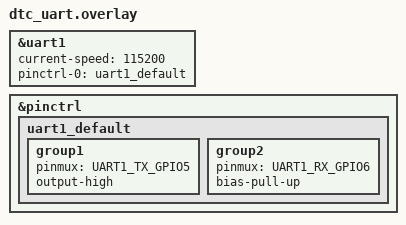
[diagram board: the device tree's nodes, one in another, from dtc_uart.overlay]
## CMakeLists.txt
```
# SPDX-License-Identifier: Apache-2.0

cmake_minimum_required(VERSION 3.20.0)
set(CONF_FILE prj.conf)
set(DTC_OVERLAY_FILE dtc_uart.overlay)

find_package(Zephyr REQUIRED HINTS $ENV{ZEPHYR_BASE})

FILE(GLOB app_sources src/*.c)
target_sources(app PRIVATE ${app_sources}
                            ./src/motordriver.c
                            ./src/rovermotor.c
                            ./src/roveruart.c
                            )
                            

project(Prac2)
```

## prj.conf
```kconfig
CONFIG_LOG=y

CONFIG_CBPRINTF_FP_SUPPORT=y

CONFIG_SHELL=y
CONFIG_SHELL_BACKENDS=y
CONFIG_SHELL_BACKEND_SERIAL=y


CONFIG_MAIN_STACK_SIZE=4096
CONFIG_I2C=y
CONFIG_SERIAL=y
CONFIG_UART_INTERRUPT_DRIVEN=y
CONFIG_UART_CONSOLE=y
```

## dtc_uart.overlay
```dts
&uart1 {
	status = "okay";
	current-speed = <115200>;
	pinctrl-0 = <&uart1_default>;
	pinctrl-names = "default";
};

&pinctrl {

	uart1_default: uart1_default {
		group1 {
			pinmux = <UART1_TX_GPIO5>;
			output-high;
		};
		group2 {
			pinmux = <UART1_RX_GPIO6>;
			bias-pull-up;
		};
	};
};
```

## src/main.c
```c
#include <stdlib.h>

#include <zephyr/kernel.h>
#include <zephyr/logging/log.h>
#include <zephyr/device.h>
#include <zephyr/shell/shell.h>
#include <zephyr/drivers/i2c.h>
#include <zephyr/drivers/uart.h>
#include "rovermotor.h"
#include "roveruart.h"
#define LOG_LEVEL 4
LOG_MODULE_REGISTER(main);

//  Global to pass to shell commands. 
struct rovermotor_info motor_control_handle; 
struct roveruart_info uart_control_handle; 
const struct device* i2c_dev = DEVICE_DT_GET(DT_NODELABEL(i2c0));
const struct device* uart_dev = DEVICE_DT_GET(DT_NODELABEL(uart1));

static int rover_cmd_cb(const struct shell* shell, size_t argc, char** argv) 
{
	int8_t vel = atoi(argv[1]); 
	int angle_percent = atoi(argv[2]); 
	float angle = ((float) (angle_percent)) / 100; 
	LOG_INF("Commanding speed: %hhi, angle: %f", vel, angle);
	rovermotor_send_instruction(&motor_control_handle, angle, vel);
	return 0;
}

static int reset_angle_cmd_cb(const struct shell* shell, size_t argc, char** argv) 
{
	roveruart_reset_angle(&uart_control_handle);
	LOG_INF("Resetting angle");
	return 0;
}
void main(void) 
{

	rovermotor_init(0x5D, 0xAB, i2c_dev, &motor_control_handle); 
	roveruart_init(uart_dev, &uart_control_handle); 
	LOG_INF("Initialized motor handler");

	SHELL_CMD_ARG_REGISTER(
        rover,
        NULL,
        "rover [speed] [angle]: set speed and angle \n"
		"speed from -127 to 127, angle from -100 to 100 (int)",
        rover_cmd_cb,
        3,
        0
    );
	SHELL_CMD_ARG_REGISTER(
        reset_angle,
        NULL,
        "Reset angle refernce\n",
		reset_angle_cmd_cb,
        0,
        0
    );
	rover_position_info_t position; 
	while (1)
	{
		// Do nothing - shell command handles it all. 
		k_sleep(K_MSEC(1000));
		int res = roveruart_get_new_position(&uart_control_handle, &position);
		if (res) {
			//LOG_INF("No new messages");
		} else {
			LOG_INF("Got position: (%hhu, %hhu)", position.x, position.y); 
		}
	}
	
	
}
```

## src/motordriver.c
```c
#include "motordriver.h"
LOG_MODULE_REGISTER(motordriver);

/**
 * initializes an instance of a driver for the Sparkfun Qwiic Motor Driver /
 * Sparkfun SCMD motor driver, on given uart device, with given device address
 */
void motordriver_init(const struct device* dev, uint8_t device_addr) 
{

    if (!device_is_ready(dev)) {
		LOG_ERR("I2C: Device is not ready.\n");
		return;
	}
    // dummy read - check the device we expect is on this bus. 
    uint8_t res;
    int status = i2c_reg_read_byte(dev, device_addr, SCMD_ID, &res);
    int num_tries = 0; 
    while (res != ID_WORD) 
    {
        LOG_INF("Couldn't get valid ID yet ... ");

        k_sleep(K_MSEC(100));
        status = i2c_reg_read_byte(dev, device_addr, SCMD_ID, &res);
        if (num_tries++ > CONN_MAX_NUM_TRIES) {
            LOG_ERR("Couldn't find driver with addr %x", device_addr);
            return; 
        };

    }
    if (status) {
        LOG_ERR("Dummy read failed");
    } else {
        LOG_INF("Found motor driver with id %x", res);
    }
    i2c_reg_write_byte(dev, device_addr, SCMD_DRIVER_ENABLE, 0x01);

    i2c_reg_read_byte(dev, device_addr, SCMD_DRIVER_ENABLE, &res);
    i2c_reg_write_byte(dev, device_addr, SCMD_BRIDGE, 0x01);
}

int motordriver_send_pwm(const struct device* dev, uint8_t device_addr, uint8_t val)
{
    int res = i2c_reg_write_byte(dev, device_addr, SCMD_MA_DRIVE, val);
    if (res) {
        return res;
    }
    res = i2c_reg_write_byte(dev, device_addr, SCMD_MB_DRIVE, val);
    return res;
    
}
```

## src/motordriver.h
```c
#ifndef _MOTOR_DRIVER_H_
#define _MOTOR_DRIVER_H_
#include <zephyr/logging/log.h>
#include <zephyr/device.h>
#include <zephyr/drivers/i2c.h>


//defaults ( Set config in PSoC, use for reference in Arduino )   
#define ID_WORD                    0xA9  //Device ID to be programmed into memory for reads
#define START_SLAVE_ADDR           0x50  //Start address of slaves
#define MAX_SLAVE_ADDR             0x5F  //Max address of slaves
#define MASTER_LOCK_KEY            0x9B
#define USER_LOCK_KEY              0x5C
#define FIRMWARE_VERSION           0x07
#define POLL_ADDRESS               0x4A  //Address of an unasigned, ready slave
#define MAX_POLL_LIMIT             0xC8  //200

//SCMD_STATUS_1 bits
#define SCMD_ENUMERATION_BIT       0x01
#define SCMD_BUSY_BIT              0x02
#define SCMD_REM_READ_BIT          0x04
#define SCMD_REM_WRITE_BIT         0x08
#define SCMD_HW_EN_BIT             0x10
 
//SCMD_CONTROL_1 bits
#define SCMD_FULL_RESET_BIT        0x01
#define SCMD_RE_ENUMERATE_BIT      0x02
    
//SCMD_FSAFE_CTRL bits and masks
#define SCMD_FSAFE_DRIVE_KILL      0x01
#define SCMD_FSAFE_RESTART_MASK    0x06
	#define SCMD_FSAFE_REBOOT          0x02
	#define SCMD_FSAFE_RE_ENUM         0x04
#define SCMD_FSAFE_CYCLE_USER      0x08
#define SCMD_FSAFE_CYCLE_EXP       0x10

//SCMD_MST_E_IN_FN bits and masks
#define SCMD_M_IN_RESTART_MASK    0x03
	#define SCMD_M_IN_REBOOT          0x01
	#define SCMD_M_IN_RE_ENUM         0x02
#define SCMD_M_IN_CYCLE_USER      0x04
#define SCMD_M_IN_CYCLE_EXP       0x08

//Address map
#define SCMD_FID                   0x00
#define SCMD_ID                    0x01
#define SCMD_SLAVE_ADDR            0x02
#define SCMD_CONFIG_BITS           0x03
#define SCMD_U_I2C_RD_ERR          0x04
#define SCMD_U_I2C_WR_ERR          0x05
#define SCMD_U_BUF_DUMPED          0x06
#define SCMD_E_I2C_RD_ERR          0x07
#define SCMD_E_I2C_WR_ERR          0x08
#define SCMD_LOOP_TIME	           0x09
#define SCMD_SLV_POLL_CNT          0x0A
#define SCMD_SLV_TOP_ADDR          0x0B
#define SCMD_MST_E_ERR             0x0C
#define SCMD_MST_E_STATUS          0x0D
#define SCMD_FSAFE_FAULTS          0x0E
#define SCMD_REG_OOR_CNT           0x0F
#define SCMD_REG_RO_WRITE_CNT      0x10
#define SCMD_GEN_TEST_WORD         0x11
#define SCMD_MOTOR_A_INVERT        0x12
#define SCMD_MOTOR_B_INVERT        0x13
#define SCMD_BRIDGE                0x14
#define SCMD_LOCAL_MASTER_LOCK     0x15
#define SCMD_LOCAL_USER_LOCK       0x16
#define SCMD_MST_E_IN_FN           0x17
#define SCMD_U_PORT_CLKDIV_U       0x18
#define SCMD_U_PORT_CLKDIV_L       0x19
#define SCMD_U_PORT_CLKDIV_CTRL    0x1A
#define SCMD_E_PORT_CLKDIV_U       0x1B
#define SCMD_E_PORT_CLKDIV_L       0x1C
#define SCMD_E_PORT_CLKDIV_CTRL    0x1D
#define SCMD_U_BUS_UART_BAUD       0x1E
#define SCMD_FSAFE_CTRL            0x1F
#define SCMD_MA_DRIVE              0x20
#define SCMD_MB_DRIVE              0x21
#define SCMD_S1A_DRIVE             0x22
#define SCMD_S1B_DRIVE             0x23
#define SCMD_S2A_DRIVE             0x24
#define SCMD_S2B_DRIVE             0x25
#define SCMD_S3A_DRIVE             0x26
#define SCMD_S3B_DRIVE             0x27
#define SCMD_S4A_DRIVE             0x28
#define SCMD_S4B_DRIVE             0x29
#define SCMD_S5A_DRIVE             0x2A
#define SCMD_S5B_DRIVE             0x2B
#define SCMD_S6A_DRIVE             0x2C
#define SCMD_S6B_DRIVE             0x2D
#define SCMD_S7A_DRIVE             0x2E
#define SCMD_S7B_DRIVE             0x2F
#define SCMD_S8A_DRIVE             0x30
#define SCMD_S8B_DRIVE             0x31
#define SCMD_S9A_DRIVE             0x32
#define SCMD_S9B_DRIVE             0x33
#define SCMD_S10A_DRIVE            0x34
#define SCMD_S10B_DRIVE            0x35
#define SCMD_S11A_DRIVE            0x36
#define SCMD_S11B_DRIVE            0x37
#define SCMD_S12A_DRIVE            0x38
#define SCMD_S12B_DRIVE            0x39
#define SCMD_S13A_DRIVE            0x3A
#define SCMD_S13B_DRIVE            0x3B
#define SCMD_S14A_DRIVE            0x3C
#define SCMD_S14B_DRIVE            0x3D
#define SCMD_S15A_DRIVE            0x3E
#define SCMD_S15B_DRIVE            0x3F
#define SCMD_S16A_DRIVE            0x40
#define SCMD_S16B_DRIVE            0x41

#define SCMD_INV_2_9               0x50
#define SCMD_INV_10_17             0x51
#define SCMD_INV_18_25             0x52
#define SCMD_INV_26_33             0x53
#define SCMD_BRIDGE_SLV_L          0x54
#define SCMD_BRIDGE_SLV_H          0x55

//#define SCMD_PAGE_SELECT           0x6F
#define SCMD_DRIVER_ENABLE         0x70
#define SCMD_UPDATE_RATE           0x71
#define SCMD_FORCE_UPDATE          0x72
#define SCMD_E_BUS_SPEED           0x73
#define SCMD_MASTER_LOCK           0x74
#define SCMD_USER_LOCK             0x75
#define SCMD_FSAFE_TIME            0x76
#define SCMD_STATUS_1              0x77
#define SCMD_CONTROL_1             0x78

#define SCMD_REM_ADDR              0x79
#define SCMD_REM_OFFSET            0x7A
#define SCMD_REM_DATA_WR           0x7B
#define SCMD_REM_DATA_RD           0x7C
#define SCMD_REM_WRITE             0x7D
#define SCMD_REM_READ              0x7E

extern void motordriver_init(const struct device* dev, uint8_t device_addr);

extern int motordriver_send_pwm(const struct device* dev, uint8_t device_addr, uint8_t val); 



#endif 
```

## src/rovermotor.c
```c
#include "rovermotor.h"
LOG_MODULE_REGISTER(rovermotor);

K_THREAD_STACK_DEFINE(rovermotor_handler_stack, ROVERMOTOR_STACK_SIZE);

/**
 * Initializes parameters stored in rovermotor handle motor_info. 
 * Creates handler thread and returns its thread ID. 
 * @param left_addr 7-bit i2c address of left-side motor controller
 * @param right_addr 7 bit i2c address of right side motor controller
 * @param dev zephyr i2c device that each motor driver is run on. 
 * @param motor_info uninitialized struct (it is initialized in this function). 
 */
k_tid_t rovermotor_init(
            uint8_t left_addr, 
            uint8_t right_addr, 
            const struct device* dev, 
            struct rovermotor_info* motor_info
            ) 
{
    motor_info->left_addr = left_addr;
    motor_info->right_addr = right_addr;
    motor_info->dev = dev; 
    
    k_msgq_init(
        &(motor_info->handler_queue), 
        motor_info->cmd_msg_buf, 
        sizeof(struct rover_queue_msg), 
        16
        );

    // Create thread and pass in handler struct to avoid global. 
    LOG_INF("Creating thread to handle rover motor control");
    return k_thread_create(&(motor_info->motor_thread_data), rovermotor_handler_stack,
		K_THREAD_STACK_SIZEOF(rovermotor_handler_stack),
		rovermotor_handler,
		(void*) (motor_info), NULL, NULL,
		ROVERMOTOR_PRIORITY, 0, K_NO_WAIT);
}

/**
 * Hanlder thread for rover motor control. Blocks until a message is received from 
 * another task (from call to rovermotor_send_instruction). 
 * First parameter is pointer to handler struct rovermotor_info
 */
void rovermotor_handler(void* handler, void*, void* )
{
    struct rovermotor_info info = *((struct rovermotor_info*) handler); 
    struct rover_queue_msg instruction; 
    int msg_rx_status; 
    // Initialize left and right motors. 
    LOG_INF("Initializing left motor");
    motordriver_init(info.dev, info.left_addr);
    LOG_INF("Initializing right motor");
    motordriver_init(info.dev, info.right_addr); 

    // Block until a message comes in, process, update motor control. 
    while (1) {
        msg_rx_status = k_msgq_get(&(info.handler_queue), (void*) (&instruction), K_FOREVER);
        if (msg_rx_status) {
            LOG_INF("Couldn't get command from queue, %i", msg_rx_status); 
        } else {
            // We have a command to instruct the motor driver. 
            // Set angular velocity - scale -100-100% (0 to 1) command
            int left = instruction.direction * ANGLE_CHANGE_RATE_CONST; 
            // Turning only - left will move at opposite speed to right
            int right = left * -1; 

            // Adjust for forward velocity - increase vel of each motor. 
            left += ((int) (instruction.velocity)) * FWD_VELOCITY_RATE_CONST;
            right += ((int) (instruction.velocity)) * FWD_VELOCITY_RATE_CONST; 
            // Map int8 range to 0-255 for motor drive. 
            uint8_t left_motor_cmd = left + 127; 
            uint8_t right_motor_cmd = right + 127; 
            // Control each motor. 
            motordriver_send_pwm(info.dev, info.left_addr, left_motor_cmd);
            motordriver_send_pwm(info.dev, info.right_addr, right_motor_cmd); 
        }
    }
    
}

/**
 * Sends instruction to rover motor control handler thread, to move rover 
 * forward at given speed, and to turn at given direction speed
 * @require direction if from -1 to 1, mapping angular velocity (like a percentage). 
 */
int rovermotor_send_instruction(
        struct rovermotor_info* motor_info, 
        float direction, 
        int8_t speed) 
{
    struct rover_queue_msg command = {
        .direction = direction,
        .velocity = speed,
    };

    int status = k_msgq_put(&(motor_info->handler_queue), (void*) (&command), K_NO_WAIT);
    if (status == -ENOMSG) {
        LOG_ERR("Couldn't send to handler: ENOMSG: Returned without waiting or queue purged.");
    } else if (status == -EAGAIN) {
        LOG_ERR("Couldn't send to handler: EAGAIN: Waiting period timed out.");
    } else if (status) {
        LOG_ERR("Couldn't send to handler: unknown error");
    }
    return status; 
}
```

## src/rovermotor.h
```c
#ifndef _ROVERMOTOR_H_
#define _ROVERMOTOR_H_
#include <stdlib.h>
#include <zephyr/kernel.h>
#define ROVERMOTOR_STACK_SIZE 4096
#define ROVERMOTOR_PRIORITY 14
#define FWD_VELOCITY_RATE_CONST 0.5
#define ANGLE_CHANGE_RATE_CONST 60
#define LOG_LEVEL 4
#include <zephyr/logging/log.h>
#include <zephyr/device.h>
#include "motordriver.h"

struct rovermotor_info {
    uint8_t left_addr;
    uint8_t right_addr;
    struct k_msgq handler_queue;
    char __aligned(4) cmd_msg_buf[16 * sizeof(float)];
    const struct device* dev; 
    struct k_thread motor_thread_data; 
};

struct rover_queue_msg {
    float direction;
    int8_t velocity; 
};

extern k_tid_t rovermotor_init (
            uint8_t left_addr, 
            uint8_t right_addr, 
            const struct device* dev, 
            struct rovermotor_info* motor_info
            );

extern int rovermotor_send_instruction(
        struct rovermotor_info* motor_info, 
        float direction, 
        int8_t speed);
        
void rovermotor_handler(void* handler, void*, void* );

#endif 
```

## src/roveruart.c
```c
#include "roveruart.h"

LOG_MODULE_REGISTER(roveruart);
int roveruart_init(const struct device* dev, struct roveruart_info* info) 
{

    int ret = uart_irq_callback_user_data_set(dev, roveruart_rx_cb, (void*) info);
	uart_irq_rx_enable(dev);
	info->dev = dev;
	return ret; 


}


void roveruart_rx_cb(const struct device* dev, void* user_data) 
{
	struct roveruart_info* info = ((struct roveruart_info*) user_data);
	uint8_t rxd;
	static int num_rxd = 0; 
	rover_position_info_t pos; 
	if (!uart_irq_update(dev)) {
		return;
	}

	if (!uart_irq_rx_ready(dev)) {
		return;
	}
	while (uart_fifo_read(dev, &rxd, 1) == 1) {
		if (rxd == MSG_PREAMBLE) {
			// Preamble byte
			num_rxd = 1; 
		} else if (num_rxd == 1) {
			pos.x = rxd;
			num_rxd++; 
		} else {
			pos.y = rxd; 
			num_rxd = 0;
			k_msgq_put(&info->receive, &pos, K_NO_WAIT);
			
		}

	}
}

// Realistically this should run more than quick enough to not need threading. 
void roveruart_reset_angle(struct roveruart_info* info) 
{
	uart_poll_out(info->dev, 0x69);
}


/**
 * Returns -EAGAIN if no message is waiting in queue, -ENOMSG if other failure, 
 * otherwsie populates pos struct pointer with values. 
 */
int roveruart_get_new_position(
		struct roveruart_info* info, 
		struct rover_position_info_t* pos) 
{
	return k_msgq_get(&(info->receive), (void*) pos, K_NO_WAIT);
}
```

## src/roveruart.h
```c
#ifndef _ROVERUART_H_
#define _ROVERUART_H_
#include <zephyr/logging/log.h>
#include <zephyr/device.h>
#include <zephyr/kernel.h>
#include <zephyr/drivers/uart.h>

#define LOG_LEVEL 4
#define MSG_PREAMBLE 0xFF
typedef uint8_t roveruart_transmit_t;

typedef struct rover_position_info_t {
    uint8_t x; 
    uint8_t y; 
} rover_position_info_t;
struct roveruart_info {
    struct k_msgq transmit; 
    char __aligned(4) transmit_buf[10 * sizeof(roveruart_transmit_t)];
    struct k_msgq receive; 
    char __aligned(4) receive_buf[10 * sizeof(rover_position_info_t)];
    const struct device* dev;
};



extern int roveruart_init(const struct device* dev, struct roveruart_info* info);
void roveruart_rx_cb(const struct device* dev, void* user_data);
int roveruart_get_new_position(
		struct roveruart_info* info, 
		struct rover_position_info_t* pos);
extern void roveruart_reset_angle(struct roveruart_info* info);

#endif 
```
